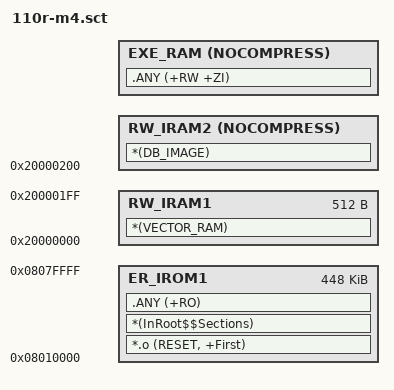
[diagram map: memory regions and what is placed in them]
; *************************************************************
; *** Scatter-Loading Description File generated by uVision ***
; *************************************************************

LR_IROM1 0x08010000 0x00070000  {    ; load region size_region
  ER_IROM1 0x08010000 0x00070000  {  ; load address = execution address
   *.o (RESET, +First)
   *(InRoot$$Sections)
   .ANY (+RO)
  }
  RW_IRAM1 0x20000000 0x00000200  {  ; VECTOR_RAM
   *(VECTOR_RAM)
  }
  RW_IRAM2 0x20000200 NOCOMPRESS     ; DB_IMAGE
  {
   *(DB_IMAGE)
  }
  
  EXE_RAM +0 NOCOMPRESS              ; for ram data
  {
   .ANY (+RW +ZI)
  }
}

